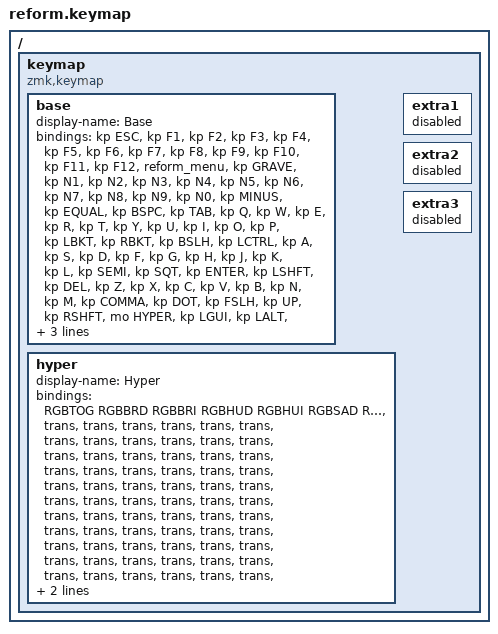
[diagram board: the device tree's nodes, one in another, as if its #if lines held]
/*
  SPDX-License-Identifier: GPL-3.0-or-later
  Copyright 2025 joguSD
*/

#include <behaviors.dtsi>
#if CONFIG_MNT_REFORM_MODE == 0 /* MNT_REFORM_MODE_STANDALONE */
#include <behaviors/reform_menu_standalone.dtsi>
#else
#include <behaviors/reform_menu.dtsi>
#endif
#include <behaviors/reform_sysctrl.dtsi>
#include <dt-bindings/zmk/keys.h>
#include <dt-bindings/zmk/mouse.h>
#include <dt-bindings/zmk/rgb.h>

#define BASE  0
#define HYPER 1

#define RGBTOG  &rgb_ug RGB_TOG
#define RGBHUI  &rgb_ug RGB_HUI
#define RGBHUD  &rgb_ug RGB_HUD
#define RGBSAI  &rgb_ug RGB_SAI
#define RGBSAD  &rgb_ug RGB_SAD
#define RGBBRI  &rgb_ug RGB_BRI
#define RGBBRD  &rgb_ug RGB_BRD
#define RGBEFF  &rgb_ug RGB_EFF


// ---------- Reform key switch positions ----------
//
// -------------------------------------------------------------------------------------------------------
// |   0  |   1  |   2  |   3  |   4  |   5  |   6  |   7  |   8  |   9  |  10  |  11  |  12  |    13    |
// -------------------------------------------------------------------------------------------------------
// |  14  |  15  |  16  |  17  |  18  |  19  |  20  |  21  |  22  |  23  |  24  |  25  |  26  |    27    |
// -------------------------------------------------------------------------------------------------------
// |    28    |  29  |  30  |  31  |  32  |  33  |  34  |  35  |  36  |  37  |  38  |  39  |  40  |  41  |
// -------------------------------------------------------------------------------------------------------
// |      42     |  43  |  44  |  45  |  46  |  47  |  48  |  49  |  50  |  51  |  52  |  53  |    54    |
// -------------------------------------------------------------------------------------------------------
// |   55    |  56  |  57  |  58  |  59  |  60  |  61  |  62  |  63  |  64  |  65  |  66  |  67  |  68   |
// -------------------------------------------------------------------------------------------------------
// |   69    |    70   |    71    |    72   |      73     |    74    |  75  |  76  |  77  |  78  |  79   |
// -------------------------------------------------------------------------------------------------------
//
// ESC(0)    F1(1)     F2(2)     F3(3)     F4(4)     F5(5)     F6(6)     F7(7)     F8(8)     F9(9)     F10(10)   F11(11)   F12(12)   CIRCLE(13)
// GRAVE(14) N1(15)    N2(16)    N3(17)    N4(18)    N5(19)    N6(20)    N7(21)    N8(22)    N9(23)    N0(24)    MINUS(25) EQUAL(26) BSPC(27)
// TAB(28)   Q(29)     W(30)     E(31)     R(32)     T(33)     Y(34)     U(35)     I(36)     O(37)     P(38)     LBRC(39)  RBRC(40)  BSLS(41)
// ECTRL(42) A(43)     S(44)     D(45)     F(46)     G(47)     H(48)     J(49)     K(50)     L(51)     SCLN(52)  QUOTE(53) ENTER(54)
// LSFT(55)  LSFT(56)  Z(57)     X(58)     C(59)     V(60)     B(61)     N(62)     M(63)     COMMA(64) DOT(65)   SLASH(66) UP(67)    RSFT(68)
// HYPER(69) LGUI(70)  LALT(71)  SPACE(72) SPACE(73)           SPACE(74) RALT(75)  RCTL(76)  LEFT(77)  DOWN(78)  RIGHT(79)


/ {
    keymap {
        compatible = "zmk,keymap";

        base {
            // Layer 0 BASE
            // -------------------------------------------------------------------------------------------------------
            // |  Esc |  F1  |  F2  |  F3  |  F4  |  F5  |  F6  |  F7  |  F8  |  F9  |  F10 |  F11 |  F12 |    Fn    |
            // -------------------------------------------------------------------------------------------------------
            // |  `~  |  1!  |  2@  |  3#  |  4$  |  5%  |  6^  |  7&  |  8*  |  9(  |  0)  |  -_  |  =+  | Backspace|
            // -------------------------------------------------------------------------------------------------------
            // |    Tab   |   Q  |   W  |   E  |   R  |   T  |   Y  |   U  |   I  |   O  |   P  |  [{  |  ]}  |  \|  |
            // -------------------------------------------------------------------------------------------------------
            // |    LCtrl    |   A  |   S  |   D  |   F  |   G  |   H  |   J  |   K  |   L  |  ;:  |  '"  |   Enter  |
            // -------------------------------------------------------------------------------------------------------
            // |  LShift |  Del |   Z  |   X  |   C  |   V  |   B  |   N  |   M  |  ,<  |  .>  |  /?  |  Up  | RShift|
            // -------------------------------------------------------------------------------------------------------
            // |   Fn    |   LGUI  |   ALT    |   Space |     Space   |  Space   | ALT | RCtrl | Left | Down |  Right|
            // -------------------------------------------------------------------------------------------------------
            display-name = "Base";
            bindings = <
                &kp ESC   &kp F1    &kp F2    &kp F3    &kp F4    &kp F5    &kp F6    &kp F7    &kp F8    &kp F9    &kp F10   &kp F11   &kp F12   &reform_menu
                &kp GRAVE &kp N1    &kp N2    &kp N3    &kp N4    &kp N5    &kp N6    &kp N7    &kp N8    &kp N9    &kp N0    &kp MINUS &kp EQUAL &kp BSPC
                &kp TAB   &kp Q     &kp W     &kp E     &kp R     &kp T     &kp Y     &kp U     &kp I     &kp O     &kp P     &kp LBKT  &kp RBKT  &kp BSLH
                &kp LCTRL &kp A     &kp S     &kp D     &kp F     &kp G     &kp H     &kp J     &kp K     &kp L     &kp SEMI  &kp SQT   &kp ENTER
                &kp LSHFT &kp DEL   &kp Z     &kp X     &kp C     &kp V     &kp B     &kp N     &kp M     &kp COMMA &kp DOT   &kp FSLH  &kp UP    &kp RSHFT
                &mo HYPER &kp LGUI  &kp LALT  &kp SPACE &kp SPACE           &kp SPACE &kp RALT  &kp RCTRL &kp LEFT  &kp DOWN  &kp RIGHT
#if CONFIG_MNT_REFORM_MODE == 2 /* MNT_REFORM_MODE_NEXT */
                &mkp LCLK &mkp MCLK &mkp RCLK
#endif
            >;
        };

        hyper {
            // Layer 1 HYPER
            // -------------------------------------------------------------------------------------------------------
            // | RTOG | RBRD | RBRI | RHUD | RHUI | RSAD | RSAI | REFF | ---- | ---- | ---- | ---- | ---- | -------- |
            // -------------------------------------------------------------------------------------------------------
            // | ---- | ---- | ---- | ---- | ---- | ---- | ---- | ---- | ---- | ---- | ---- | ---- | ---- | -------- |
            // -------------------------------------------------------------------------------------------------------
            // | -------- | ---- | ---- | ---- | ---- | ---- | ---- | ---- | ---- | ---- | ---- | ---- | ---- | ---- |
            // -------------------------------------------------------------------------------------------------------
            // | ----------- | ---- | ---- | ---- | ---- | ---- | ---- | ---- | ---- | ---- | ---- | ---- | -------- |
            // -------------------------------------------------------------------------------------------------------
            // | ------- | ---- | ---- | ---- | ---- | ---- | ---- | ---- | ---- | ---- | ---- | ---- | ---- | ----- |
            // -------------------------------------------------------------------------------------------------------
            // | ------- | ------- | -------- | ------- | ----------- | -------- | --- | ----- | ---- | ---- | ----- |
            // -------------------------------------------------------------------------------------------------------
            display-name = "Hyper";
            bindings = <
                RGBTOG    RGBBRD    RGBBRI    RGBHUD    RGBHUI    RGBSAD    RGBSAI    RGBEFF    &trans    &trans    &trans    &trans    &trans    &trans
                &trans    &trans    &trans    &trans    &trans    &trans    &trans    &trans    &trans    &trans    &trans    &trans    &trans    &trans
                &trans    &trans    &trans    &trans    &trans    &trans    &trans    &trans    &trans    &trans    &trans    &trans    &trans    &trans
                &trans    &trans    &trans    &trans    &trans    &trans    &trans    &trans    &trans    &trans    &trans    &trans    &trans
                &trans    &trans    &trans    &trans    &trans    &trans    &trans    &trans    &trans    &trans    &trans    &trans    &trans    &trans
                &trans    &trans    &trans    &trans    &trans              &trans    &trans    &trans    &trans    &trans    &trans
#if CONFIG_MNT_REFORM_MODE == 2 /* MNT_REFORM_MODE_NEXT */
                &trans    &trans    &trans
#endif
            >;
        };

        extra1 {
            status = "reserved";
        };

        extra2 {
            status = "reserved";
        };

        extra3 {
            status = "reserved";
        };
    };
};
